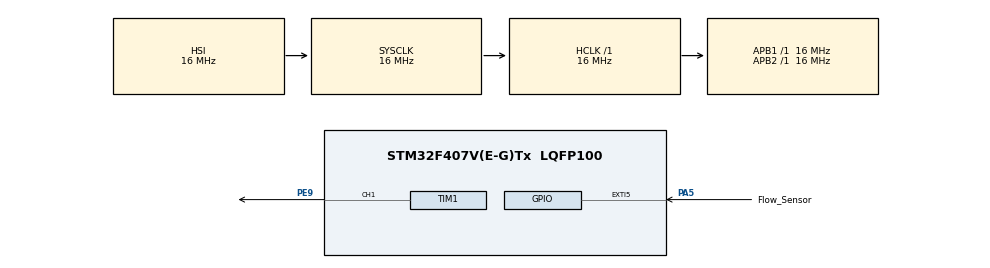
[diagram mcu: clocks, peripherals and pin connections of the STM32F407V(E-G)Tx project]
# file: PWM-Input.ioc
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FREERTOS.Tasks01=defaultTask,0,128,StartDefaultTask,Default,NULL
Mcu.Family=STM32F4
Mcu.Name=STM32F407V(E-G)Tx
Mcu.Package=LQFP100
NVIC.EXTI9_5_IRQn=true\:5\:0\:false\:false\:true\:true\:true
NVIC.PriorityGroup=NVIC_PRIORITYGROUP_4
NVIC.TIM2_IRQn=true\:0\:0\:false\:false\:true\:false\:true
NVIC.TimeBase=TIM2_IRQn
NVIC.TimeBaseIP=TIM2
PA5.GPIO_Label=Flow_Sensor
PA5.Signal=GPXTI5
PE9.Signal=S_TIM1_CH1
ProjectManager.HeapSize=0x200
ProjectManager.StackSize=0x400
ProjectManager.TargetToolchain=SW4STM32
RCC.48MHZClocksFreq_Value=96000000
RCC.AHBFreq_Value=16000000
RCC.APB1Freq_Value=16000000
RCC.APB1TimFreq_Value=16000000
RCC.APB2Freq_Value=16000000
RCC.APB2TimFreq_Value=16000000
RCC.CortexFreq_Value=16000000
RCC.HCLKFreq_Value=16000000
RCC.HSE_VALUE=8000000
RCC.HSI_VALUE=16000000
RCC.LSE_VALUE=32768
RCC.PLLM=8
RCC.SYSCLKFreq_VALUE=16000000
RCC.VCOOutputFreq_Value=384000000
SH.S_TIM1_CH1.0=TIM1_CH1,Output Compare1 CH1
TIM1.Channel-Output\ Compare1\ CH1=TIM_CHANNEL_1
VP_FREERTOS_VS_ENABLE.Mode=Enabled
VP_SYS_VS_tim2.Mode=TIM2
VP_TIM1_VS_ClockSourceINT.Mode=Internal
board=PWM-Input

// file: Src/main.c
/**
  ******************************************************************************
  * File Name          : main.c
  * Description        : Main program body
  ******************************************************************************
  * This notice applies to any and all portions of this file
  * that are not between comment pairs USER CODE BEGIN and
  * USER CODE END. Other portions of this file, whether
  * inserted by the user or by software development tools
  * are owned by their respective copyright owners.
  *
  * Copyright (c) 2018 STMicroelectronics International N.V.
  * All rights reserved.
  *
  * Redistribution and use in source and binary forms, with or without
  * modification, are permitted, provided that the following conditions are met:
  *
  * 1. Redistribution of source code must retain the above copyright notice,
  *    this list of conditions and the following disclaimer.
  * 2. Redistributions in binary form must reproduce the above copyright notice,
  *    this list of conditions and the following disclaimer in the documentation
  *    and/or other materials provided with the distribution.
  * 3. Neither the name of STMicroelectronics nor the names of other
  *    contributors to this software may be used to endorse or promote products
  *    derived from this software without specific written permission.
  * 4. This software, including modifications and/or derivative works of this
  *    software, must execute solely and exclusively on microcontroller or
  *    microprocessor devices manufactured by or for STMicroelectronics.
  * 5. Redistribution and use of this software other than as permitted under
  *    this license is void and will automatically terminate your rights under
  *    this license.
  *
  * THIS SOFTWARE IS PROVIDED BY STMICROELECTRONICS AND CONTRIBUTORS "AS IS"
  * AND ANY EXPRESS, IMPLIED OR STATUTORY WARRANTIES, INCLUDING, BUT NOT
  * LIMITED TO, THE IMPLIED WARRANTIES OF MERCHANTABILITY, FITNESS FOR A
  * PARTICULAR PURPOSE AND NON-INFRINGEMENT OF THIRD PARTY INTELLECTUAL PROPERTY
  * RIGHTS ARE DISCLAIMED TO THE FULLEST EXTENT PERMITTED BY LAW. IN NO EVENT
  * SHALL STMICROELECTRONICS OR CONTRIBUTORS BE LIABLE FOR ANY DIRECT, INDIRECT,
  * INCIDENTAL, SPECIAL, EXEMPLARY, OR CONSEQUENTIAL DAMAGES (INCLUDING, BUT NOT
  * LIMITED TO, PROCUREMENT OF SUBSTITUTE GOODS OR SERVICES; LOSS OF USE, DATA,
  * OR PROFITS; OR BUSINESS INTERRUPTION) HOWEVER CAUSED AND ON ANY THEORY OF
  * LIABILITY, WHETHER IN CONTRACT, STRICT LIABILITY, OR TORT (INCLUDING
  * NEGLIGENCE OR OTHERWISE) ARISING IN ANY WAY OUT OF THE USE OF THIS SOFTWARE,
  * EVEN IF ADVISED OF THE POSSIBILITY OF SUCH DAMAGE.
  *
  ******************************************************************************
  */
#include "main.h"
#include "stm32f4xx_hal.h"
#include "cmsis_os.h"

/* USER CODE BEGIN Includes */
#define FLOW_CONSTANT 0.26
/* USER CODE END Includes */

TIM_HandleTypeDef htim1;

osThreadId defaultTaskHandle;

/* USER CODE BEGIN PV */
/* Private variables ---------------------------------------------------------*/
uint16_t flow_counter;
int delay_time = 1000; // 1 second
double flow;
/* USER CODE END PV */

void SystemClock_Config(void);
static void MX_GPIO_Init(void);
static void MX_TIM1_Init(void);
void StartDefaultTask(void const * argument);
void HAL_TIM_MspPostInit(TIM_HandleTypeDef *htim);

/* USER CODE BEGIN PFP */
/* Private function prototypes -----------------------------------------------*/

/* USER CODE END PFP */

/* USER CODE BEGIN 0 */
void flow_rate(void *p) {
	flow = 0.0;
	flow_counter = 0;
	for (;;) {
		vTaskDelay(delay_time);
		flow = (double) flow_counter / delay_time * 1000 * FLOW_CONSTANT;
		flow_counter = 0;
	}
}
/* USER CODE END 0 */

int main(void)
{

  /* MCU Configuration----------------------------------------------------------*/

  /* Reset of all peripherals, Initializes the Flash interface and the Systick. */
  HAL_Init();

  /* Configure the system clock */
  SystemClock_Config();

  /* Initialize all configured peripherals */
  MX_GPIO_Init();
  MX_TIM1_Init();

  /* Create the thread(s) */
  /* definition and creation of defaultTask */
  osThreadDef(defaultTask, StartDefaultTask, osPriorityNormal, 0, 128);
  defaultTaskHandle = osThreadCreate(osThread(defaultTask), NULL);

  /* USER CODE BEGIN RTOS_QUEUES */
  /* add queues, ... */
  xTaskCreate(flow_rate, (unsigned char*)"flow_rate", 1024, NULL, 1, NULL);
  /* USER CODE END RTOS_QUEUES */

  /* Start scheduler */
  osKernelStart();

  /* We should never get here as control is now taken by the scheduler */

  /* Infinite loop */
  while (1)
  {

  }

}

/** System Clock Configuration
*/
void SystemClock_Config(void)
{

  RCC_OscInitTypeDef RCC_OscInitStruct;
  RCC_ClkInitTypeDef RCC_ClkInitStruct;

    /**Configure the main internal regulator output voltage
    */
  __HAL_RCC_PWR_CLK_ENABLE();

  __HAL_PWR_VOLTAGESCALING_CONFIG(PWR_REGULATOR_VOLTAGE_SCALE1);

    /**Initializes the CPU, AHB and APB busses clocks
    */
  RCC_OscInitStruct.OscillatorType = RCC_OSCILLATORTYPE_HSI;
  RCC_OscInitStruct.HSIState = RCC_HSI_ON;
  RCC_OscInitStruct.HSICalibrationValue = 16;
  RCC_OscInitStruct.PLL.PLLState = RCC_PLL_NONE;
  if (HAL_RCC_OscConfig(&RCC_OscInitStruct) != HAL_OK)
  {
    _Error_Handler(__FILE__, __LINE__);
  }

    /**Initializes the CPU, AHB and APB busses clocks
    */
  RCC_ClkInitStruct.ClockType = RCC_CLOCKTYPE_HCLK|RCC_CLOCKTYPE_SYSCLK
                              |RCC_CLOCKTYPE_PCLK1|RCC_CLOCKTYPE_PCLK2;
  RCC_ClkInitStruct.SYSCLKSource = RCC_SYSCLKSOURCE_HSI;
  RCC_ClkInitStruct.AHBCLKDivider = RCC_SYSCLK_DIV1;
  RCC_ClkInitStruct.APB1CLKDivider = RCC_HCLK_DIV1;
  RCC_ClkInitStruct.APB2CLKDivider = RCC_HCLK_DIV1;

  if (HAL_RCC_ClockConfig(&RCC_ClkInitStruct, FLASH_LATENCY_0) != HAL_OK)
  {
    _Error_Handler(__FILE__, __LINE__);
  }

    /**Configure the Systick interrupt time
    */
  HAL_SYSTICK_Config(HAL_RCC_GetHCLKFreq()/1000);

    /**Configure the Systick
    */
  HAL_SYSTICK_CLKSourceConfig(SYSTICK_CLKSOURCE_HCLK);

  /* SysTick_IRQn interrupt configuration */
  HAL_NVIC_SetPriority(SysTick_IRQn, 15, 0);
}

/* TIM1 init function */
static void MX_TIM1_Init(void)
{

  TIM_ClockConfigTypeDef sClockSourceConfig;
  TIM_MasterConfigTypeDef sMasterConfig;
  TIM_OC_InitTypeDef sConfigOC;
  TIM_BreakDeadTimeConfigTypeDef sBreakDeadTimeConfig;

  htim1.Instance = TIM1;
  htim1.Init.Prescaler = 0;
  htim1.Init.CounterMode = TIM_COUNTERMODE_UP;
  htim1.Init.Period = 0;
  htim1.Init.ClockDivision = TIM_CLOCKDIVISION_DIV1;
  htim1.Init.RepetitionCounter = 0;
  if (HAL_TIM_Base_Init(&htim1) != HAL_OK)
  {
    _Error_Handler(__FILE__, __LINE__);
  }

  sClockSourceConfig.ClockSource = TIM_CLOCKSOURCE_INTERNAL;
  if (HAL_TIM_ConfigClockSource(&htim1, &sClockSourceConfig) != HAL_OK)
  {
    _Error_Handler(__FILE__, __LINE__);
  }

  if (HAL_TIM_OC_Init(&htim1) != HAL_OK)
  {
    _Error_Handler(__FILE__, __LINE__);
  }

  sMasterConfig.MasterOutputTrigger = TIM_TRGO_RESET;
  sMasterConfig.MasterSlaveMode = TIM_MASTERSLAVEMODE_DISABLE;
  if (HAL_TIMEx_MasterConfigSynchronization(&htim1, &sMasterConfig) != HAL_OK)
  {
    _Error_Handler(__FILE__, __LINE__);
  }

  sConfigOC.OCMode = TIM_OCMODE_TIMING;
  sConfigOC.Pulse = 0;
  sConfigOC.OCPolarity = TIM_OCPOLARITY_HIGH;
  sConfigOC.OCNPolarity = TIM_OCNPOLARITY_HIGH;
  sConfigOC.OCFastMode = TIM_OCFAST_DISABLE;
  sConfigOC.OCIdleState = TIM_OCIDLESTATE_RESET;
  sConfigOC.OCNIdleState = TIM_OCNIDLESTATE_RESET;
  if (HAL_TIM_OC_ConfigChannel(&htim1, &sConfigOC, TIM_CHANNEL_1) != HAL_OK)
  {
    _Error_Handler(__FILE__, __LINE__);
  }

  sBreakDeadTimeConfig.OffStateRunMode = TIM_OSSR_DISABLE;
  sBreakDeadTimeConfig.OffStateIDLEMode = TIM_OSSI_DISABLE;
  sBreakDeadTimeConfig.LockLevel = TIM_LOCKLEVEL_OFF;
  sBreakDeadTimeConfig.DeadTime = 0;
  sBreakDeadTimeConfig.BreakState = TIM_BREAK_DISABLE;
  sBreakDeadTimeConfig.BreakPolarity = TIM_BREAKPOLARITY_HIGH;
  sBreakDeadTimeConfig.AutomaticOutput = TIM_AUTOMATICOUTPUT_DISABLE;
  if (HAL_TIMEx_ConfigBreakDeadTime(&htim1, &sBreakDeadTimeConfig) != HAL_OK)
  {
    _Error_Handler(__FILE__, __LINE__);
  }

  HAL_TIM_MspPostInit(&htim1);

}

/** Configure pins as
        * Analog
        * Input
        * Output
        * EVENT_OUT
        * EXTI
*/
static void MX_GPIO_Init(void)
{

  GPIO_InitTypeDef GPIO_InitStruct;

  /* GPIO Ports Clock Enable */
  __HAL_RCC_GPIOA_CLK_ENABLE();
  __HAL_RCC_GPIOE_CLK_ENABLE();

  /*Configure GPIO pin : Flow_Sensor_Pin */
  GPIO_InitStruct.Pin = Flow_Sensor_Pin;
  GPIO_InitStruct.Mode = GPIO_MODE_IT_RISING;
  GPIO_InitStruct.Pull = GPIO_NOPULL;
  HAL_GPIO_Init(Flow_Sensor_GPIO_Port, &GPIO_InitStruct);

  /* EXTI interrupt init*/
  HAL_NVIC_SetPriority(EXTI9_5_IRQn, 5, 0);
  HAL_NVIC_EnableIRQ(EXTI9_5_IRQn);

}

/* StartDefaultTask function */
void StartDefaultTask(void const * argument)
{

  for(;;)
  {
    osDelay(1);
  }
}

void HAL_TIM_PeriodElapsedCallback(TIM_HandleTypeDef *htim)
{
  if (htim->Instance == TIM2) {
    HAL_IncTick();
  }
}

void _Error_Handler(char * file, int line)
{
  while(1)
  {
  }
}

/************************ (C) COPYRIGHT STMicroelectronics *****END OF FILE****/
